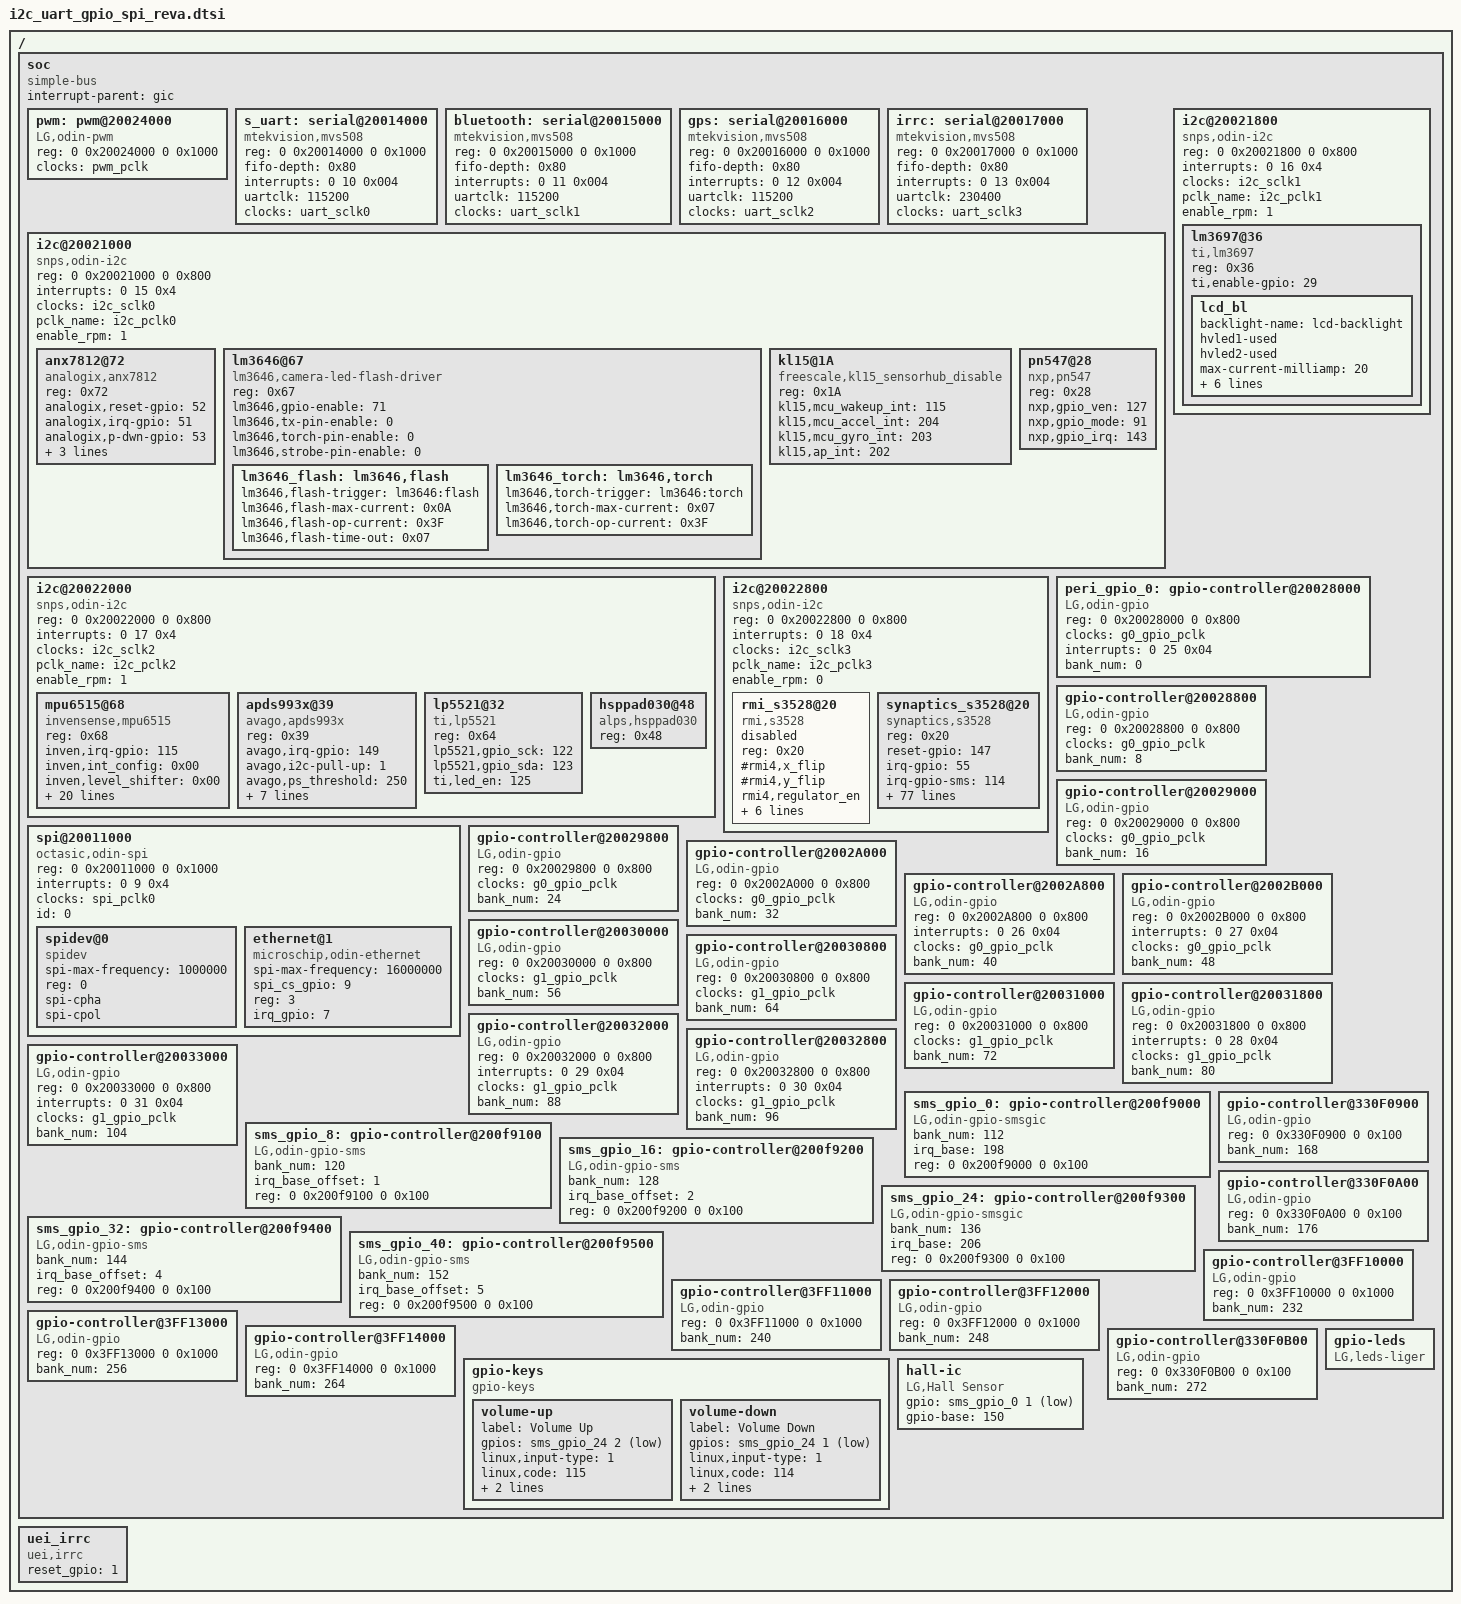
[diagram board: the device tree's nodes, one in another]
/*
 * LG Electronics I2C for ODIN/Woden
 */

/ {
	soc{
		compatible = "simple-bus";
		interrupt-parent = <&gic>;
		#address-cells = <2>;
		#size-cells = <2>;
		ranges;

		pwm: pwm@20024000 {
			compatible = "LG,odin-pwm";
			reg = <0 0x20024000 0 0x1000>;
			clocks = <&pwm_pclk>;
			#pwm-cells = <3>;
		};

		s_uart: serial@20014000 {
			compatible = "mtekvision,mvs508";
			reg = <0 0x20014000 0 0x1000>;
			fifo-depth = <0x80>;
			interrupts = <0 10 0x004>;
			uartclk = <115200>;
			clocks = <&uart_sclk0>;
		};

		bluetooth: serial@20015000 {
			compatible = "mtekvision,mvs508";
			reg = <0 0x20015000 0 0x1000>;
			fifo-depth = <0x80>;
			interrupts = <0 11 0x004>;
			uartclk = <115200>;
			clocks = <&uart_sclk1>;
		};

		gps: serial@20016000 {
			compatible = "mtekvision,mvs508";
			reg = <0 0x20016000 0 0x1000>;
			fifo-depth = <0x80>;
			interrupts = <0 12 0x004>;
			uartclk = <115200>;
			clocks = <&uart_sclk2>;
		};
/* LGE_CHANGE_S
 */
            irrc: serial@20017000 {
                      compatible = "mtekvision,mvs508";
                      reg = <0 0x20017000 0 0x1000>;
                      fifo-depth = <0x80>;
                      interrupts = <0 13 0x004>;
                      uartclk = <230400>;
                      clocks = <&uart_sclk3>;
                  };
/* LGE_CHANGE_E */


/* i2c start */

		i2c@20021000 {
			compatible = "snps,odin-i2c";
			reg = <0 0x20021000 0 0x800>;
			interrupts = <0 15 0x4>;
			clocks = <&i2c_sclk0>;
			pclk_name = "i2c_pclk0";
			enable_rpm = <1>;
			#address-cells = <1>;
			#size-cells = <0>;

			/* LGE_CHANGE_S
			 */
			anx7812@72{
				compatible = "analogix,anx7812";
				status = "ok";
				reg = <0x72>;
				analogix,reset-gpio = <52>; /* PERI_G0_GPIO_BASE(0)+52 */
				analogix,irq-gpio = <51>;   /* PERI_G0_GPIO_BASE(0)+51 */
				analogix,p-dwn-gpio = <53>; /* PERI_G0_GPIO_BASE(0)+53 */
				analogix,v10-ctrl-gpio = <31>;  /* PERI_G0_GPIO_BASE(0)+31 */
				analogix,cbl-det-gpio = <142>;  /* SMS_GPIO_BASE(112)+30 */
				lge,external-ldo-control = <0>;
			};
/* LGE_CHANGE_E*/
				lm3646@67 {
				compatible = "lm3646,camera-led-flash-driver";
				reg = <0x67>;
				lm3646,gpio-enable = <71>;
				lm3646,tx-pin-enable = <0>;
				lm3646,torch-pin-enable = <0>;
				lm3646,strobe-pin-enable =<0>;

				lm3646_flash: lm3646,flash {
				lm3646,flash-trigger = "lm3646:flash";
				lm3646,flash-max-current = <0x0A>;
				lm3646,flash-op-current = <0x3F>;
//				lm3646,flash-ramp-time = <0x0>;
				lm3646,flash-time-out = <0x07>;
				};
				lm3646_torch: lm3646,torch {
				lm3646,torch-trigger = "lm3646:torch";
				lm3646,torch-max-current = <0x07>;
				lm3646,torch-op-current = <0x3F>;
				};
			};

/*
* LGE_CHANGE_S
*/
			kl15@1A{
				compatible = "freescale,kl15_sensorhub_disable";
				reg = <0x1A>;
				kl15,mcu_wakeup_int = <115>;
				kl15,mcu_accel_int = <204>;
				kl15,mcu_gyro_int = <203>;
				kl15,ap_int = <202>;
			};
/* LGE_CHANGE_E*/
/*
* LGE_CHANGE_S
*/
                        pn547@28 {
                                compatible = "nxp,pn547";
                                reg = <0x28>;
                                nxp,gpio_ven = <127>;	/* 112 + SMS_GPIO_15_EINT */
                                nxp,gpio_mode = <91>;	/* 56 + PERI_G1_GPIO_35_EINT */
                                nxp,gpio_irq = <143>;	/* 112 + SMS_GPIO_31_EINT */
                                /* interrupt-parent = <&gic>; */
                                /* interrupts = <0 111 0x2>; */
                        };
/* LGE_CHANGE_E*/
		};
		i2c@20021800 {
			compatible = "snps,odin-i2c";
			reg = <0 0x20021800 0 0x800>;
			interrupts = <0 16 0x4>;
			clocks = <&i2c_sclk1>;
			pclk_name = "i2c_pclk1";
			enable_rpm = <1>;
			#address-cells = <1>;
			#size-cells = <0>;

			lm3697@36 {
				compatible = "ti,lm3697";
				reg = <0x36>;

				/* GPIO for HWEN pin */
				ti,enable-gpio = <29>;

				lcd_bl {
					backlight-name = "lcd-backlight";
					hvled1-used;
					hvled2-used;

					max-current-milliamp = <20>;
					initial-brightness = <178>;
					/* mapping-mode, 0:exp, 1:linear */
					mapping-mode = <1>;
					blmap_size = <256>;
										blmap = <
							17	17	18	18	18	19	19	20	20	20	21	21	21	22	22	22
							23	23	23	24	24	25	25	25	26	26	26	27	27	27	28	28
							29	29	29	30	30	30	31	31	31	32	32	32	33	33	34	34
							34	35	35	36	37	38	39	40	41	42	43	44	45	47	48	49
							50	51	52	53	54	55	56	57	58	59	60	61	62	63	64	65
							66	68	69	70	71	72	73	74	75	76	77	78	82	87	91	96
							100	104	109	113	118	122	127	131	135	140	144	149	153	157	162	166	
							171	175	180	184	188	193	197	202	206	210	215	219	224	228	233	237
							241	246	250	255	259	267	275	283	291	299	307	315	323	331	339	347
							355	363	371	379	387	395	403	411	419	427	435	443	451	459	467	475
							483	491	499	507	515	523	531	539	547	555	563	571	579	587	599	612
							624	637	649	662	674	686	699	711	724	736	749	761	774	786	798	811
							823	836	848	861	873	885	898	910	923	935	948	960	973	985	997	1010
							1022	1035	1047	1060	1072	1085	1097	1115
							1132	1149	1167	1184	1202	1219	1237	1254
							1272	1289	1307	1324	1342	1359	1377	1394
							1412	1429	1447	1464	1482	1499	1517	1534
							1552	1569	1587	1604	1622	1639	1657	1674
							1692	1709	1727	1744	1762	1779	1797	1814
							>;

					pwm-period = <1>;
				};
			};
		};

		i2c@20022000 {
			compatible = "snps,odin-i2c";
			reg = <0 0x20022000 0 0x800>;
			interrupts = <0 17 0x4>;
			clocks = <&i2c_sclk2>;
			pclk_name = "i2c_pclk2";
			enable_rpm = <1>;
			#address-cells = <1>;
			#size-cells = <0>;
/* LGE_CHANGE_S
*/
			mpu6515@68{
				compatible = "invensense,mpu6515";
				reg = <0x68>;
				inven,irq-gpio = <115>;		/*	SMS_GPIO_BASE(112) + 3	*/
				inven,int_config = <0x00>;
				inven,level_shifter = <0x00>;
				/* inven,secondary_type = "none"; */
				inven,aux_type = "none";
				inven,key = [4e cc 7e eb f6 1e 35 22 00 34 0d 65 32 e9 94 89];
				axis_map_x = <1>;
				axis_map_y = <0>;
				axis_map_z = <2>;
				negate_x = <0>;
				negate_y = <1>;
				negate_z = <0>;

				poll_interval = <200>;
				min_interval = <5>;
				inven,secondary_reg = <0x0C>;
				/* If no compass sensor,
				* replace "compass" with "none"
				*/
				inven,secondary_type = "compass";
				inven,secondary_name = "ak09911";
				inven,secondary_axis_map_x = <1>;
				inven,secondary_axis_map_y = <0>;
				inven,secondary_axis_map_z = <2>;
				inven,secondary_negate_x = <0>;
				inven,secondary_negate_y = <0>;
				inven,secondary_negate_z = <1>;
			};
/* LGE_CHANGE_E */

/* LGE_CHANGE_S
*/
			apds993x@39 {
				compatible = "avago,apds993x";
				reg = <0x39>;
				avago,irq-gpio = <149>;
				avago,i2c-pull-up = <1>;
				avago,ps_threshold = <250>;
				avago,ps_hysteresis_threshold = <150>;
				avago,ps_pulse = <6>;
				avago,ps_pgain = <0x08>;
				avago,als_B = <186>;
				avago,als_C = <75>;
				avago,als_D = <132>;
				avago,ga_value = <238>;
			};

			lp5521@32 {
				compatible = "ti,lp5521";
				reg = <0x64>;
				status = "ok";
				lp5521,gpio_sck = <122>;	/* SMS_GPIO_BASE(112)+10 */
				lp5521,gpio_sda = <123>;	/* SMS_GPIO_BASE(112)+11 */
				ti,led_en = <125>;
			};

			hsppad030@48 {
				compatible = "alps,hsppad030";
				reg = <0x48>;
			};
/* temperature / humidity sensors removed from Liger
			shtc1@70 {
				compatible = "sensirion,shtc1";
				reg = <0x70>;
			};
*/
		};
/* LGE_CHANGE_E */

		i2c@20022800 {
			compatible = "snps,odin-i2c";
			reg = <0 0x20022800 0 0x800>;
			interrupts = <0 18 0x4>;
			clocks = <&i2c_sclk3>;
			pclk_name = "i2c_pclk3";
			enable_rpm = <0>;
			#address-cells = <1>;
			#size-cells = <0>;



			rmi_s3528@20  {
				compatible = "rmi,s3528";
				status = "disable";
				reg = <0x20>;
				#rmi4,x_flip;
				#rmi4,y_flip;
				rmi4,regulator_en;
				rmi4,reset_gpio = <147>;
				rmi4,irq_gpio = <55>;
				rmi4,irq_gpio_sms = <114>;
				rmi4,irq_flags = <0x00000002>;
				rmi4,panel_x = <1080>;
				rmi4,panel_y = <1920>;
			};

			synaptics_s3528@20 {
				compatible = "synaptics,s3528";
				status = "ok";
				reg = <0x20>;
				reset-gpio = <147>;
				irq-gpio = <55>;
				irq-gpio-sms = <114>;

				/*Caps*/
				button_support = <0>;
				number_of_button = <4>;
				button_name = [9e 8b 66 d9];
				max_x = <1080>;
				max_y = <1920>;
				max_pressure = <0xff>;
				max_width = <15>;
				max_orientation = <1>;
				max_id = <10>;
				/*role*/
				protocol_type = <1>;
				report_mode = <0>;
				delta_pos_threshold = <1>;
				report_period = <10000000>;
				booting_delay = <150>;
				reset_delay = <10>;
				wake_up_by_touch = <1>;
				use_sleep_mode = <1>;
				thermal_check = <1>;
				palm_ctrl_mode = <0>;
				irqflags = <0x00000002>;
				bouncing.enable = <0>;
				grip.enable = <0>;
				grip.edge_region = <5>;
				grip.max_delta = <10>;
				grip.width_ratio = <2>;
				accuracy.enable = <0>;
				accuracy.min_delta = <3>;
				accuracy.curr_ratio = <5>;
				accuracy.min_pressure = <50>;
				jitter.enable = <0>;
				jitter.curr_ratio = <115>;
				quickcover.enable = <1>;
				quickcover.X1 = <180>;
				quickcover.X2 = <900>;
				quickcover.Y1 = <4>;
				quickcover.Y2 = <724>;
				crack.enable = <1>;
				crack.min.cap = <300>;
				/*ghost_detection -S*/
				ghost_detection_enable = <0>;
				ghost_detection_chk_cnt = <3>;
				jitter_value = <10>;
				ta_noise_chk = <0>;
				incoming_call_chk = <0>;
				first_finger_chk = <1>;
				first_finger_time = <200>;
				pressure_zero_chk = <1>;
				ta_debouncing_chk = <0>;
				ta_debouncing_cnt =<2>;
				ta_debouncing_finger_num = <2>;
				press_interval_chk = <1>;
				press_interval = <29>;
				diff_fingers_chk = <1>;
				diff_finger_num = <5>;
				subtraction_finger_chk = <1>;
				subtraction_time = <11>;
				subtraction_finger_cnt = <5>;
				long_press_chk = <1>;
				long_press_chk_time = <10>;
				long_press_cnt = <700>;
				button_chk = <0>;
				button_int_num = <6>;
				button_duration = <100>;
				rebase_repetition_chk = <1>;
				rebase_since_init = <3>;
				rebase_since_rebase = <5>;
				use_lpwg_all = <0>;
				/*ghost_detection -E*/
				/*pwr*/
				use_regulator = <1>;
				vdd = "+3.0V_TOUCH_AVCC";
				vdd_voltage = <3300000>;
				vio = "+1.8V_TOUCH_IOVCC";
				vio_voltage = <1800000>;
				/*firmware*/
				need_upgrade = <1>;
				/* Rx & Tx cap*/
				tx_cap = <5 10 2 9 7 5 1 2 2 1 10 2 3 83 7 2 8 0 10 0 5 8 4 8 6 40 88>;
				rx_cap = <53 12 15 26 28 13 27 25 4 15 5 6 22 9 44>;
				/* 1:sd. 2:ref_rebase. 3:TX. 4:RX.*/
				ref_chk_option = <0 0 1 1>;
			};

/* LGE_CHANGE_E */
		};
/* i2c end */

/* spi start */
		spi@20011000 {
			compatible = "octasic,odin-spi";
			reg = <0 0x20011000 0 0x1000>;
			interrupts = <0 9 0x4>;
			clocks = <&spi_pclk0>;
			id = <0>;
			#address-cells = <1>;
			#size-cells = <0>;

			spidev@0{
				compatible = "spidev";
				spi-max-frequency = <1000000>;
				reg = <0>;
				spi-cpha;
				spi-cpol;
			};

			ethernet@1{
				compatible = "microschip,odin-ethernet";
				spi-max-frequency = <16000000>;
				spi_cs_gpio = <9>;
				reg = <3>;
				irq_gpio = <7>;
			};
		};

/* spi end */
/*---- peri gpio controller ----*/
/* G0_GPIO0~6 */
/*
 * LGE_CHANGE_S
 */
		peri_gpio_0: gpio-controller@20028000 {
			compatible = "LG,odin-gpio";
			#gpio-cells = <2>;
			reg = <0 0x20028000 0 0x800>;
			clocks = <&g0_gpio_pclk>;
			interrupts = <0 25 0x04>;
			bank_num = <0>;
		};
/* LGE_CHANGE_E */
		gpio-controller@20028800 {
			compatible = "LG,odin-gpio";
			reg = <0 0x20028800 0 0x800>;
			clocks = <&g0_gpio_pclk>;
			bank_num = <8>;
		};
		gpio-controller@20029000 {
			compatible = "LG,odin-gpio";
			reg = <0 0x20029000 0 0x800>;
			clocks = <&g0_gpio_pclk>;
			bank_num = <16>;
		};
		gpio-controller@20029800 {
			compatible = "LG,odin-gpio";
			reg = <0 0x20029800 0 0x800>;
			clocks = <&g0_gpio_pclk>;
			bank_num = <24>;
		};
		gpio-controller@2002A000 {
			compatible = "LG,odin-gpio";
			reg = <0 0x2002A000 0 0x800>;
			clocks = <&g0_gpio_pclk>;
			bank_num = <32>;
		};
		gpio-controller@2002A800 {
			compatible = "LG,odin-gpio";
			reg = <0 0x2002A800 0 0x800>;
			interrupts = <0 26 0x04>;
			clocks = <&g0_gpio_pclk>;
			bank_num = <40>;
		};
		gpio-controller@2002B000 {
			compatible = "LG,odin-gpio";
			reg = <0 0x2002B000 0 0x800>;
			interrupts = <0 27 0x04>;
			clocks = <&g0_gpio_pclk>;
			bank_num = <48>;
		};
	/* G1_GPIO0~6 */
		gpio-controller@20030000 {
			compatible = "LG,odin-gpio";
			reg = <0 0x20030000 0 0x800>;
			clocks = <&g1_gpio_pclk>;
			bank_num = <56>;
		};
		gpio-controller@20030800 {
			compatible = "LG,odin-gpio";
			reg = <0 0x20030800 0 0x800>;
			clocks = <&g1_gpio_pclk>;
			bank_num = <64>;
		};
		gpio-controller@20031000 {
			compatible = "LG,odin-gpio";
			reg = <0 0x20031000 0 0x800>;
			clocks = <&g1_gpio_pclk>;
			bank_num = <72>;
		};
		gpio-controller@20031800 {
			compatible = "LG,odin-gpio";
			reg = <0 0x20031800 0 0x800>;
			interrupts = <0 28 0x04>;
			clocks = <&g1_gpio_pclk>;
			bank_num = <80>;
		};
		gpio-controller@20032000 {
			compatible = "LG,odin-gpio";
			reg = <0 0x20032000 0 0x800>;
			interrupts = <0 29 0x04>;
			clocks = <&g1_gpio_pclk>;
			bank_num = <88>;
		};
		gpio-controller@20032800 {
			compatible = "LG,odin-gpio";
			reg = <0 0x20032800 0 0x800>;
			interrupts = <0 30 0x04>;
			clocks = <&g1_gpio_pclk>;
			bank_num = <96>;
		};
		gpio-controller@20033000 {
			compatible = "LG,odin-gpio";
			reg = <0 0x20033000 0 0x800>;
			interrupts = <0 31 0x04>;
			clocks = <&g1_gpio_pclk>;
			bank_num = <104>;
		};
	/*---- peri gpio controller end ----*/

/*
LGE_CHANGE_S
*/
	/*---- sms gpio controller ----*/
		sms_gpio_0: gpio-controller@200f9000 {
			compatible = "LG,odin-gpio-smsgic";
			bank_num = <112>;
			irq_base = <198>;
			reg = <0 0x200f9000 0 0x100>;
		};
		sms_gpio_8: gpio-controller@200f9100 {
			compatible = "LG,odin-gpio-sms";
			bank_num = <120>;
			irq_base_offset = <1>;
			reg = <0 0x200f9100 0 0x100>;
		};
		sms_gpio_16: gpio-controller@200f9200 {
			compatible = "LG,odin-gpio-sms";
			bank_num = <128>;
			irq_base_offset = <2>;
			reg = <0 0x200f9200 0 0x100>;
		};
		sms_gpio_24: gpio-controller@200f9300 {
			compatible = "LG,odin-gpio-smsgic";
			#gpio-cells = <2>;
			bank_num = <136>;
			irq_base = <206>;
			reg = <0 0x200f9300 0 0x100>;
		};
		sms_gpio_32: gpio-controller@200f9400 {
			compatible = "LG,odin-gpio-sms";
			bank_num = <144>;
			irq_base_offset = <4>;
			reg = <0 0x200f9400 0 0x100>;
		};
		sms_gpio_40: gpio-controller@200f9500 {
			compatible = "LG,odin-gpio-sms";
			bank_num = <152>;
			irq_base_offset = <5>;
			reg = <0 0x200f9500 0 0x100>;
		};
	/*---- sms gpio controller end ----*/
/* LGE_CHANGE_E */

	/*---- css gpio controller ----*/
		gpio-controller@330F0900 {
			compatible = "LG,odin-gpio";
			reg = <0 0x330F0900 0 0x100>;
			bank_num = <168>;
		};
		gpio-controller@330F0A00 {
			compatible = "LG,odin-gpio";
			reg = <0 0x330F0A00 0 0x100>;
			bank_num = <176>;
		};
/*---- css gpio controller end ----*/

/*
* LGE_CHANGE_S
*/
	/*---- ics gpio controller start ----*/
		gpio-controller@3FF10000 {
			compatible = "LG,odin-gpio";
			reg = <0 0x3FF10000 0 0x1000>;
			bank_num = <232>;
		};
		gpio-controller@3FF11000 {
			compatible = "LG,odin-gpio";
			reg = <0 0x3FF11000 0 0x1000>;
			bank_num = <240>;
		};
		gpio-controller@3FF12000 {
			compatible = "LG,odin-gpio";
			reg = <0 0x3FF12000 0 0x1000>;
			bank_num = <248>;
		};
		gpio-controller@3FF13000 {
			compatible = "LG,odin-gpio";
			reg = <0 0x3FF13000 0 0x1000>;
			bank_num = <256>;
		};
		gpio-controller@3FF14000 {
			compatible = "LG,odin-gpio";
			reg = <0 0x3FF14000 0 0x1000>;
			bank_num = <264>;
		};
	/*---- ics gpio controller end ----*/
/* LGE_CHANGE_E */
/* LGE_CHANGE_S */
	/*---- css gpio controller ----*/
		gpio-controller@330F0B00 {
			compatible = "LG,odin-gpio";
			reg = <0 0x330F0B00 0 0x100>;
			bank_num = <272>;
		};
	/*---- css gpio controller end ----*/
/* LGE_CHANGE_E */
/*
 * LGE_CHANGE_S
 */
	gpio-keys {
		compatible = "gpio-keys";
		volume-up {
			label = "Volume Up";
			gpios = <&sms_gpio_24 2 1>;
			linux,input-type = <1>;
			linux,code = <115>; 	/* KEY_VOLUMEUP */
			gpio-key,wakeup;
			debounce-interval = <15>;
			};
		volume-down {
			label = "Volume Down";
			gpios = <&sms_gpio_24 1 1>;
			linux,input-type = <1>;
			linux,code = <114>; 	/* KEY_VOLUMEDOWN */
			gpio-key,wakeup;
			debounce-interval = <15>;
			};
/*
LGE_CHANGE_S
*/
/*
		home {
			label = "Home";
			gpios = <&sms_gpio_0 1 0x1>;
			linux,code = <172>;
			gpio-key,wakeup;
			};
*/
/* LGE_CHANGE_E */

	};
/* LGE_CHANGE_E */

	hall-ic {
		compatible = "LG,Hall Sensor";
		gpio = <&sms_gpio_0 1 0x1>;
		gpio-base = <150>;	/* 112+SMS_GPIO_38 */
	};

/*
 * LGE_CHANGE_S
 */
	gpio-leds {
		compatible = "LG,leds-liger";
		};
/* LGE_CHANGE_E */
	};
/*
 * LGE_CHANGE_S
*/
        uei_irrc {
            compatible = "uei,irrc";
            /* PERI_GPIO(0) + GPIO(1) = 1 */
            reset_gpio = <1>;
        };
/* LGE_CHANGE_E */
};
